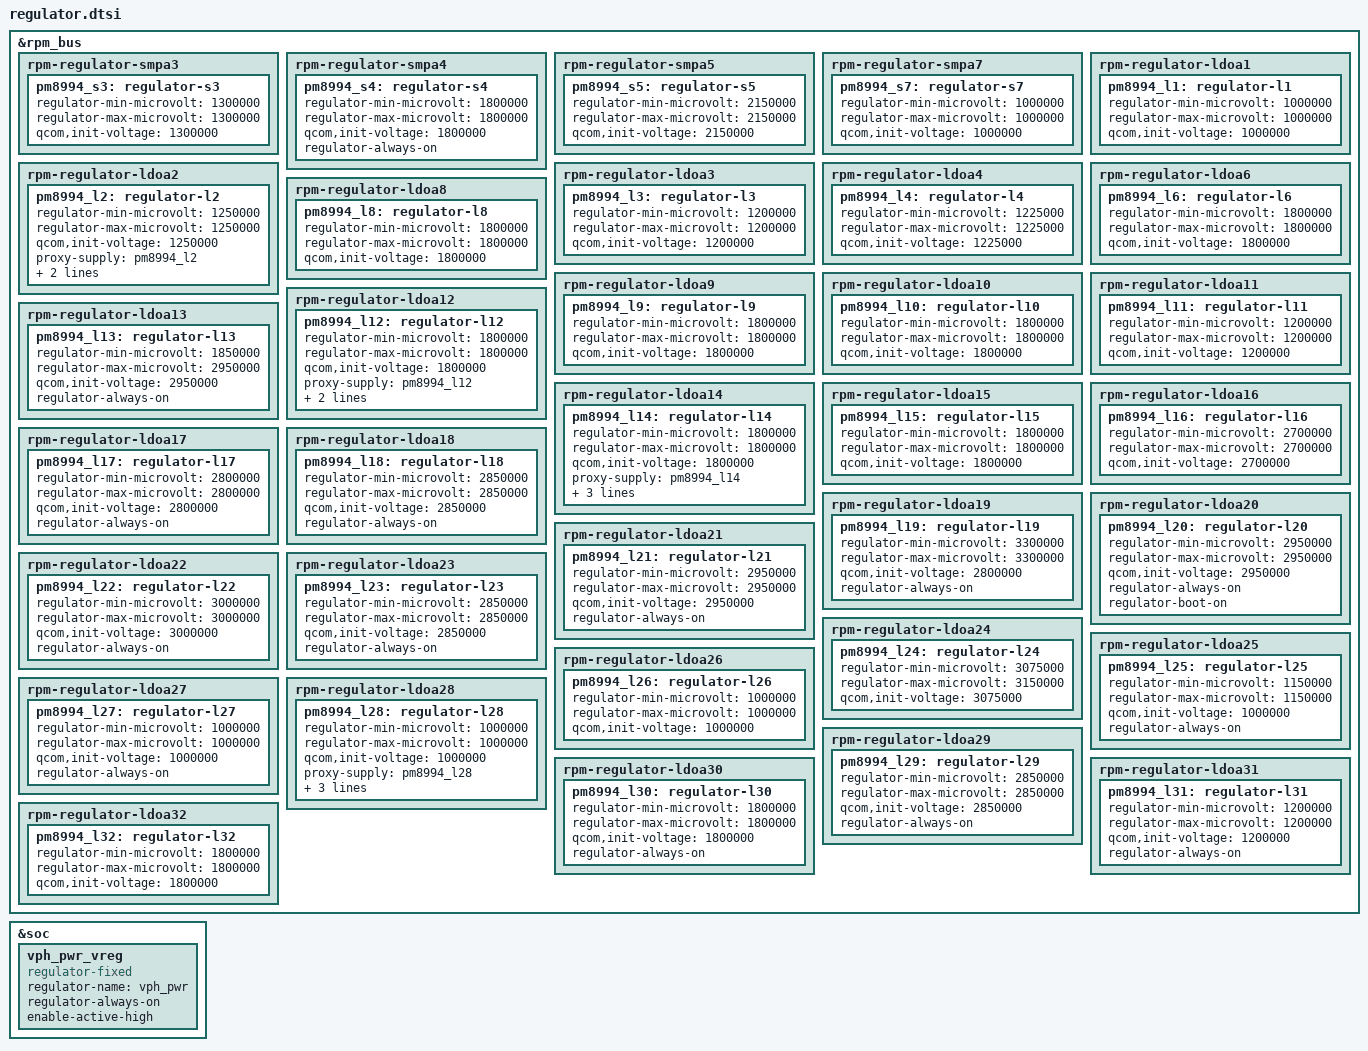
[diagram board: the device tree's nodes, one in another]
/* Copyright (c) 2014-2015, The Linux Foundation. All rights reserved.
 *
 * This program is free software; you can redistribute it and/or modify
 * it under the terms of the GNU General Public License version 2 and
 * only version 2 as published by the Free Software Foundation.
 *
 * This program is distributed in the hope that it will be useful,
 * but WITHOUT ANY WARRANTY; without even the implied warranty of
 * MERCHANTABILITY or FITNESS FOR A PARTICULAR PURPOSE.  See the
 * GNU General Public License for more details.
 */

&rpm_bus {
	rpm-regulator-smpa3 {
		status = "okay";
		pm8994_s3: regulator-s3 {
			regulator-min-microvolt = <1300000>;
			regulator-max-microvolt = <1300000>;
			qcom,init-voltage = <1300000>;
			status = "okay";
		};
	};

	rpm-regulator-smpa4 {
		status = "okay";
		pm8994_s4: regulator-s4 {
			regulator-min-microvolt = <1800000>;
			regulator-max-microvolt = <1800000>;
			qcom,init-voltage = <1800000>;
            regulator-always-on;
			status = "okay";
		};
	};

	rpm-regulator-smpa5 {
		status = "okay";
		pm8994_s5: regulator-s5 {
			regulator-min-microvolt = <2150000>;
			regulator-max-microvolt = <2150000>;
			qcom,init-voltage = <2150000>;
			status = "okay";
		};
	};

	rpm-regulator-smpa7 {
		status = "okay";
		pm8994_s7: regulator-s7 {
			regulator-min-microvolt = <1000000>;
			regulator-max-microvolt = <1000000>;
			qcom,init-voltage = <1000000>;
			status = "okay";
		};
	};

	rpm-regulator-ldoa1 {
		status = "okay";
		pm8994_l1: regulator-l1 {
			regulator-min-microvolt = <1000000>;
			regulator-max-microvolt = <1000000>;
			qcom,init-voltage = <1000000>;
			status = "okay";
		};
	};

	rpm-regulator-ldoa2 {
		status = "okay";
		pm8994_l2: regulator-l2 {
			regulator-min-microvolt = <1250000>;
			regulator-max-microvolt = <1250000>;
			qcom,init-voltage = <1250000>;
			proxy-supply = <&pm8994_l2>;
			qcom,proxy-consumer-enable;
			qcom,proxy-consumer-current = <10000>;
			status = "okay";
		};
	};

	rpm-regulator-ldoa3 {
		status = "okay";
		pm8994_l3: regulator-l3 {
			regulator-min-microvolt = <1200000>;
			regulator-max-microvolt = <1200000>;
			qcom,init-voltage = <1200000>;
			status = "okay";
		};
	};

	rpm-regulator-ldoa4 {
		status = "okay";
		pm8994_l4: regulator-l4 {
			regulator-min-microvolt = <1225000>;
			regulator-max-microvolt = <1225000>;
			qcom,init-voltage = <1225000>;
			status = "okay";
		};
	};

	rpm-regulator-ldoa6 {
		status = "okay";
		pm8994_l6: regulator-l6 {
			regulator-min-microvolt = <1800000>;
			regulator-max-microvolt = <1800000>;
			qcom,init-voltage = <1800000>;
			status = "okay";
		};
	};

	rpm-regulator-ldoa8 {
		status = "okay";
		pm8994_l8: regulator-l8 {
			regulator-min-microvolt = <1800000>;
			regulator-max-microvolt = <1800000>;
			qcom,init-voltage = <1800000>;
			status = "okay";
		};
	};

	rpm-regulator-ldoa9 {
		status = "okay";
		pm8994_l9: regulator-l9 {
			regulator-min-microvolt = <1800000>;
			regulator-max-microvolt = <1800000>;
			qcom,init-voltage = <1800000>;
			status = "okay";
		};
	};

	rpm-regulator-ldoa10 {
		status = "okay";
		pm8994_l10: regulator-l10 {
			regulator-min-microvolt = <1800000>;
			regulator-max-microvolt = <1800000>;
			qcom,init-voltage = <1800000>;
			status = "okay";
		};
	};

	rpm-regulator-ldoa11 {
		status = "okay";
		pm8994_l11: regulator-l11 {
			regulator-min-microvolt = <1200000>;
			regulator-max-microvolt = <1200000>;
			qcom,init-voltage = <1200000>;
			status = "okay";
		};
	};

	rpm-regulator-ldoa12 {
		status = "okay";
		pm8994_l12: regulator-l12 {
			regulator-min-microvolt = <1800000>;
			regulator-max-microvolt = <1800000>;
			qcom,init-voltage = <1800000>;
			proxy-supply = <&pm8994_l12>;
			qcom,proxy-consumer-enable;
			qcom,proxy-consumer-current = <10000>;
			status = "okay";
		};
	};

	rpm-regulator-ldoa13 {
		status = "okay";
		pm8994_l13: regulator-l13 {
			regulator-min-microvolt = <1850000>;
			regulator-max-microvolt = <2950000>;
			qcom,init-voltage = <2950000>;
            regulator-always-on;
			status = "okay";
		};
	};

	rpm-regulator-ldoa14 {
		status = "okay";
		pm8994_l14: regulator-l14 {
			regulator-min-microvolt = <1800000>;
			regulator-max-microvolt = <1800000>;
			qcom,init-voltage = <1800000>;
			proxy-supply = <&pm8994_l14>;
			qcom,proxy-consumer-enable;
			qcom,proxy-consumer-current = <10000>;
            regulator-always-on;
			status = "okay";
		};
	};

	rpm-regulator-ldoa15 {
		status = "okay";
		pm8994_l15: regulator-l15 {
			regulator-min-microvolt = <1800000>;
			regulator-max-microvolt = <1800000>;
			qcom,init-voltage = <1800000>;
			status = "okay";
		};
	};

	rpm-regulator-ldoa16 {
		status = "okay";
		pm8994_l16: regulator-l16 {
			regulator-min-microvolt = <2700000>;
			regulator-max-microvolt = <2700000>;
			qcom,init-voltage = <2700000>;
			status = "okay";
		};
	};

	rpm-regulator-ldoa17 {
		status = "okay";
		pm8994_l17: regulator-l17 {
			regulator-min-microvolt = <2800000>;
			regulator-max-microvolt = <2800000>;
			qcom,init-voltage = <2800000>;
			regulator-always-on;
			status = "okay";
		};
	};

	rpm-regulator-ldoa18 {
		status = "okay";
		pm8994_l18: regulator-l18 {
			regulator-min-microvolt = <2850000>;
			regulator-max-microvolt = <2850000>;
			qcom,init-voltage = <2850000>;
			regulator-always-on;
			status = "okay";
		};
	};

	rpm-regulator-ldoa19 {
		status = "okay";
		pm8994_l19: regulator-l19 {
			regulator-min-microvolt = <3300000>;
			regulator-max-microvolt = <3300000>;
			qcom,init-voltage = <2800000>;
			regulator-always-on;
			status = "okay";
		};
	};

	rpm-regulator-ldoa20 {
		status = "okay";
		pm8994_l20: regulator-l20 {
			regulator-min-microvolt = <2950000>;
			regulator-max-microvolt = <2950000>;
			qcom,init-voltage = <2950000>;
			regulator-always-on;
			regulator-boot-on;
			status = "okay";
		};
	};

	rpm-regulator-ldoa21 {
		status = "okay";
		pm8994_l21: regulator-l21 {
			regulator-min-microvolt = <2950000>;
			regulator-max-microvolt = <2950000>;
			qcom,init-voltage = <2950000>;
			regulator-always-on;
			status = "okay";
		};
	};

	rpm-regulator-ldoa22 {
		status = "okay";
		pm8994_l22: regulator-l22 {
			regulator-min-microvolt = <3000000>;
			regulator-max-microvolt = <3000000>;
			qcom,init-voltage = <3000000>;
			regulator-always-on;
			status = "okay";
		};
	};

	rpm-regulator-ldoa23 {
		status = "okay";
		pm8994_l23: regulator-l23 {
			regulator-min-microvolt = <2850000>;
			regulator-max-microvolt = <2850000>;
			qcom,init-voltage = <2850000>;
			regulator-always-on;
			status = "okay";
		};
	};

	rpm-regulator-ldoa24 {
		status = "okay";
		pm8994_l24: regulator-l24 {
			regulator-min-microvolt = <3075000>;
			regulator-max-microvolt = <3150000>;
			qcom,init-voltage = <3075000>;
			status = "okay";
		};
	};

	rpm-regulator-ldoa25 {
		status = "okay";
		pm8994_l25: regulator-l25 {
			regulator-min-microvolt = <1150000>;
			regulator-max-microvolt = <1150000>;
			qcom,init-voltage = <1000000>;
			regulator-always-on;
			status = "okay";
		};
	};

	rpm-regulator-ldoa26 {
		status = "okay";
		pm8994_l26: regulator-l26 {
			regulator-min-microvolt = <1000000>;
			regulator-max-microvolt = <1000000>;
			qcom,init-voltage = <1000000>;
			status = "okay";
		};
	};

	rpm-regulator-ldoa27 {
		status = "okay";
		pm8994_l27: regulator-l27 {
			regulator-min-microvolt = <1000000>;
			regulator-max-microvolt = <1000000>;
			qcom,init-voltage = <1000000>;
			regulator-always-on;
			status = "okay";
		};
	};

	rpm-regulator-ldoa28 {
		status = "okay";
		pm8994_l28: regulator-l28 {
			regulator-min-microvolt = <1000000>;
			regulator-max-microvolt = <1000000>;
			qcom,init-voltage = <1000000>;
			proxy-supply = <&pm8994_l28>;
			qcom,proxy-consumer-enable;
			qcom,proxy-consumer-current = <10000>;
			regulator-always-on;
			status = "okay";
		};
	};

	rpm-regulator-ldoa29 {
		status = "okay";
		pm8994_l29: regulator-l29 {
			regulator-min-microvolt = <2850000>;
			regulator-max-microvolt = <2850000>;
			qcom,init-voltage = <2850000>;
			regulator-always-on;
			status = "okay";
		};
	};

	rpm-regulator-ldoa30 {
		status = "okay";
		pm8994_l30: regulator-l30 {
			regulator-min-microvolt = <1800000>;
			regulator-max-microvolt = <1800000>;
			qcom,init-voltage = <1800000>;
			regulator-always-on;
			status = "okay";
		};
	};

	rpm-regulator-ldoa31 {
		status = "okay";
		pm8994_l31: regulator-l31 {
			regulator-min-microvolt = <1200000>;
			regulator-max-microvolt = <1200000>;
			qcom,init-voltage = <1200000>;
			regulator-always-on;
			status = "okay";
		};
	};

	rpm-regulator-ldoa32 {
		status = "okay";
		pm8994_l32: regulator-l32 {
			regulator-min-microvolt = <1800000>;
			regulator-max-microvolt = <1800000>;
			qcom,init-voltage = <1800000>;
			status = "okay";
		};
	};
};

&soc {
	/*
	 * vph_pwr_vreg represents the unregulated battery voltage supply
	 * VPH_PWR that is present whenever the device is powered on.
	 */
	 vph_pwr_vreg: vph_pwr_vreg {
		compatible = "regulator-fixed";
		regulator-name = "vph_pwr";
		status = "ok";
		regulator-always-on;
		enable-active-high;
	};
};
